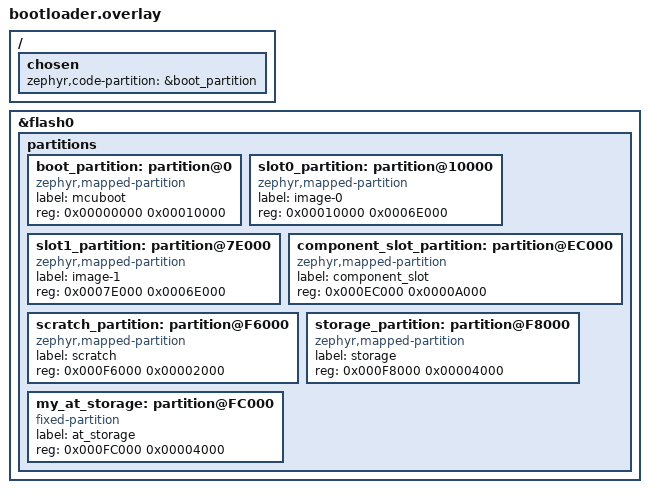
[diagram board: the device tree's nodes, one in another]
/ {
	chosen {
		zephyr,code-partition = &boot_partition;
	};
};

&flash0 {
	partitions {
		ranges;
		#address-cells = <1>;
		#size-cells = <1>;
		/delete-node/ partition@c000;
		/delete-node/ partition@82000;

		boot_partition: partition@0 {
			compatible = "zephyr,mapped-partition";
			label = "mcuboot";
			reg = <0x00000000 0x00010000>;
		};

		slot0_partition: partition@10000 {
			compatible = "zephyr,mapped-partition";
			label = "image-0";
			reg = <0x00010000 0x0006E000>;
		};

		slot1_partition: partition@7E000 {
			compatible = "zephyr,mapped-partition";
			label = "image-1";
			reg = <0x0007E000 0x0006E000>;
		};

		component_slot_partition: partition@EC000 {
			compatible = "zephyr,mapped-partition";
			label = "component_slot";
			reg = <0x000EC000 0x0000A000>;
		};

		scratch_partition: partition@F6000 {
			compatible = "zephyr,mapped-partition";
			label = "scratch";
			reg = <0x000F6000 0x00002000>;
		};

		storage_partition: partition@F8000 {
			compatible = "zephyr,mapped-partition";
			label = "storage";
			reg = <0x000F8000 0x00004000>;
		};

		my_at_storage: partition@FC000 {
			compatible = "fixed-partition";
			label = "at_storage";
			reg = <0x000FC000 0x00004000>;
		};
	};
};
